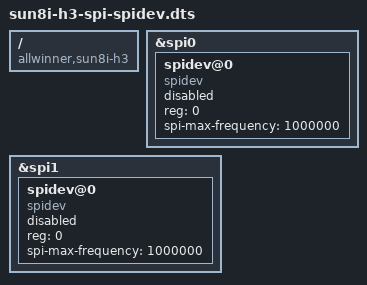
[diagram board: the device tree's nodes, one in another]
/dts-v1/;
/plugin/;

/ {
	compatible = "allwinner,sun8i-h3";
};

&spi0 {
	#address-cells = <1>;
	#size-cells = <0>;
	spidev@0 {
		compatible = "spidev";
		status = "disabled";
		reg = <0>;
		spi-max-frequency = <1000000>;
	};
};

&spi1 {
	#address-cells = <1>;
	#size-cells = <0>;
	spidev@0 {
		compatible = "spidev";
		status = "disabled";
		reg = <0>;
		spi-max-frequency = <1000000>;
	};
};
